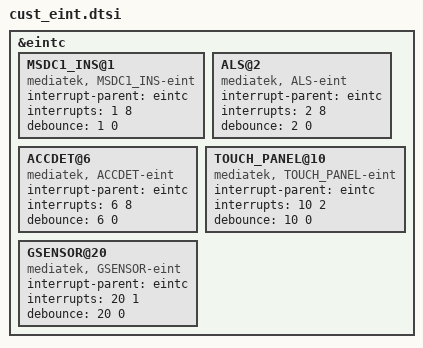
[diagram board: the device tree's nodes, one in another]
/*
 * Generated by MTK SP DrvGen Version 03.13.6 for MT6753. Copyright MediaTek Inc. (C) 2013.
 * Thu Nov 12 14:31:13 2015
 * Do Not Modify the File.
 */

/*************************
 * EINT DTSI File
*************************/

&eintc {
	MSDC1_INS@1 {
		compatible = "mediatek, MSDC1_INS-eint";
		interrupt-parent = <&eintc>;
		interrupts = <1 8>;
		debounce = <1 0>;
	};

	ALS@2 {
		compatible = "mediatek, ALS-eint";
		interrupt-parent = <&eintc>;
		interrupts = <2 8>;
		debounce = <2 0>;
	};

	ACCDET@6 {
		compatible = "mediatek, ACCDET-eint";
		interrupt-parent = <&eintc>;
		interrupts = <6 8>;
		debounce = <6 0>;
	};

	TOUCH_PANEL@10 {
		compatible = "mediatek, TOUCH_PANEL-eint";
		interrupt-parent = <&eintc>;
		interrupts = <10 2>;
		debounce = <10 0>;
	};

	GSENSOR@20 {
		compatible = "mediatek, GSENSOR-eint";
		interrupt-parent = <&eintc>;
		interrupts = <20 1>;
		debounce = <20 0>;
	};

};
